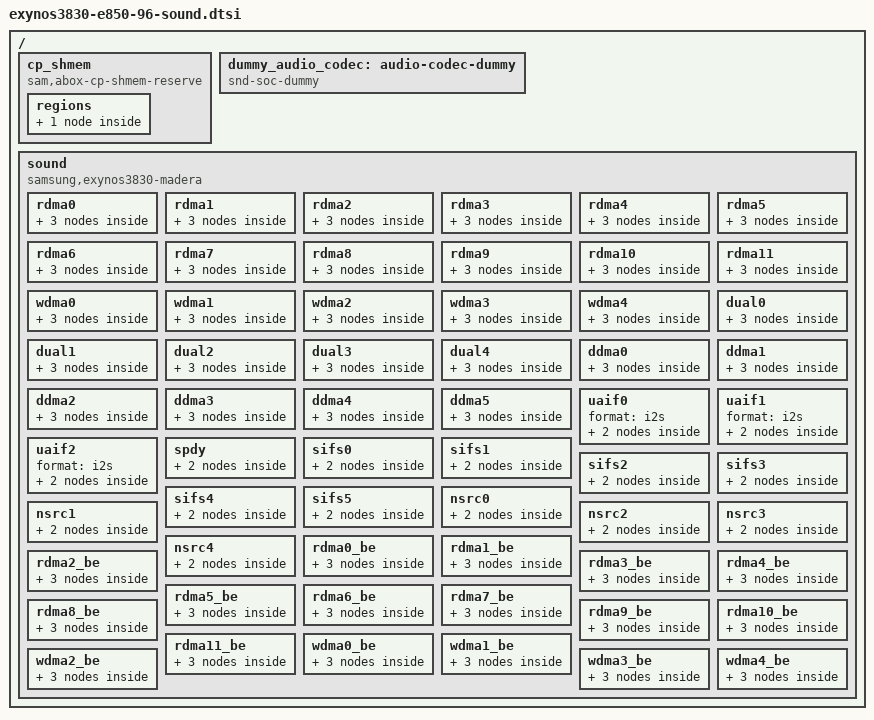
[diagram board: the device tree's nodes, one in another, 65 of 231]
/*
 * SAMSUNG EXYNOS3830 board device tree source
 *
 * Copyright (c) 2018 Samsung Electronics Co., Ltd.
 *		http://www.samsung.com
 *
 * This program is free software; you can redistribute it and/or modify
 * it under the terms of the GNU General Public License version 2 as
 * published by the Free Software Foundation.
 */

/ {
	fragment@sound {
		target-path = "/";
		__overlay__ {
			/*
			 * XXX: This is excerpt from
			 * exynos3830-erd3830-cp-s318ap-sit.dtsi for reserving
			 * memory region used by ABOX (audio) firmware as a
			 * shared memory. If it's not reserved, there will be
			 * MMU translation fault interrupt, leading to kernel
			 * panic. CP (modem) is not present on E850-96 board,
			 * so it's only a workaround to avoid kernel panic.
			 *
			 * Once audio firmware is fixed properly, remove this
			 * node along with CONFIG_SAM_ABOX_CP_SHMEM_RESERVE.
			 */
			cp_shmem {
				compatible = "sam,abox-cp-shmem-reserve";

				cp_num = <0>;
				use_mem_map_on_cp = <1>;

				regions {
					cp {
						region,name = "CP";
						/* 0 = SHMEM_CP */
						region,index = <0>;
						region,rmem = <0>;
						region,offset = <0x00000000>;
						region,size = <0x07900000>;
						region,cached = <0>;
					};
				};
			}; /* end of cp_shmem */

			dummy_audio_codec: audio-codec-dummy {
				compatible = "snd-soc-dummy";
				#sound-dai-cells = <0>;
			};

			sound {
				compatible = "samsung,exynos3830-madera";

				samsung,routing = "ABOX SPDY Capture", "VINPUT_FM",
					"BLUETOOTH SPK", "ABOX UAIF2 Playback",
					"ABOX UAIF2 Capture", "BLUETOOTH MIC";

				samsung,codec = <&abox &abox_uaif_0 &abox_uaif_1 &abox_uaif_2
					&abox_spdy &abox_tplg
					&abox_rdma_0 &abox_rdma_1 &abox_rdma_2 &abox_rdma_3
					&abox_rdma_4 &abox_rdma_5 &abox_rdma_6 &abox_rdma_7
					&abox_rdma_8 &abox_rdma_9 &abox_rdma_10 &abox_rdma_11
					&abox_wdma_0 &abox_wdma_1 &abox_wdma_2 &abox_wdma_3
					&abox_wdma_4 &abox_ddma_0 &abox_ddma_1 &abox_ddma_2
					&abox_ddma_3 &abox_ddma_4 &abox_ddma_5>;
				samsung,prefix = "ABOX", "ABOX", "ABOX", "ABOX",
					"ABOX", "ABOX",
					"ABOX RDMA0", "ABOX RDMA1", "ABOX RDMA2", "ABOX RDMA3",
					"ABOX RDMA4", "ABOX RDMA5", "ABOX RDMA6", "ABOX RDMA7",
					"ABOX RDMA8", "ABOX RDMA9", "ABOX RDMA10", "ABOX RDMA11",
					"ABOX WDMA0", "ABOX WDMA1", "ABOX WDMA2", "ABOX WDMA3",
					"ABOX WDMA4", "ABOX DBG0", "ABOX DBG1", "ABOX DBG2",
					"ABOX DBG3", "ABOX DBG4", "ABOX DBG5";

				samsung,aux = <&abox_tplg>;

				rdma0 {
					cpu {
						sound-dai = <&abox_rdma_0 0>;
					};
					platform {
						sound-dai = <&abox_rdma_0 0>;
					};
					codec {
						sound-dai = <&dummy_audio_codec>;
					};
				};
				rdma1 {
					cpu {
						sound-dai = <&abox_rdma_1 0>;
					};
					platform {
						sound-dai = <&abox_rdma_1 0>;
					};
					codec {
						sound-dai = <&dummy_audio_codec>;
					};
				};
				rdma2 {
					cpu {
						sound-dai = <&abox_rdma_2 0>;
					};
					platform {
						sound-dai = <&abox_rdma_2 0>;
					};
					codec {
						sound-dai = <&dummy_audio_codec>;
					};
				};
				rdma3 {
					cpu {
						sound-dai = <&abox_rdma_3 0>;
					};
					platform {
						sound-dai = <&abox_rdma_3 0>;
					};
					codec {
						sound-dai = <&dummy_audio_codec>;
					};
				};
				rdma4 {
					cpu {
						sound-dai = <&abox_rdma_4 0>;
					};
					platform {
						sound-dai = <&abox_rdma_4 0>;
					};
					codec {
						sound-dai = <&dummy_audio_codec>;
					};
				};
				rdma5 {
					cpu {
						sound-dai = <&abox_rdma_5 0>;
					};
					platform {
						sound-dai = <&abox_rdma_5 0>;
					};
					codec {
						sound-dai = <&dummy_audio_codec>;
					};
				};
				rdma6 {
					cpu {
						sound-dai = <&abox_rdma_6 0>;
					};
					platform {
						sound-dai = <&abox_rdma_6 0>;
					};
					codec {
						sound-dai = <&dummy_audio_codec>;
					};
				};
				rdma7 {
					cpu {
						sound-dai = <&abox_rdma_7 0>;
					};
					platform {
						sound-dai = <&abox_rdma_7 0>;
					};
					codec {
						sound-dai = <&dummy_audio_codec>;
					};
				};
				rdma8 {
					cpu {
						sound-dai = <&abox_rdma_8 0>;
					};
					platform {
						sound-dai = <&abox_rdma_8 0>;
					};
					codec {
						sound-dai = <&dummy_audio_codec>;
					};
				};
				rdma9 {
					cpu {
						sound-dai = <&abox_rdma_9 0>;
					};
					platform {
						sound-dai = <&abox_rdma_9 0>;
					};
					codec {
						sound-dai = <&dummy_audio_codec>;
					};
				};
				rdma10 {
					cpu {
						sound-dai = <&abox_rdma_10 0>;
					};
					platform {
						sound-dai = <&abox_rdma_10 0>;
					};
					codec {
						sound-dai = <&dummy_audio_codec>;
					};
				};
				rdma11 {
					cpu {
						sound-dai = <&abox_rdma_11 0>;
					};
					platform {
						sound-dai = <&abox_rdma_11 0>;
					};
					codec {
						sound-dai = <&dummy_audio_codec>;
					};
				};
				wdma0 {
					cpu {
						sound-dai = <&abox_wdma_0 0>;
					};
					platform {
						sound-dai = <&abox_wdma_0 0>;
					};
					codec {
						sound-dai = <&dummy_audio_codec>;
					};
				};
				wdma1 {
					cpu {
						sound-dai = <&abox_wdma_1 0>;
					};
					platform {
						sound-dai = <&abox_wdma_1 0>;
					};
					codec {
						sound-dai = <&dummy_audio_codec>;
					};
				};
				wdma2 {
					cpu {
						sound-dai = <&abox_wdma_2 0>;
					};
					platform {
						sound-dai = <&abox_wdma_2 0>;
					};
					codec {
						sound-dai = <&dummy_audio_codec>;
					};
				};
				wdma3 {
					cpu {
						sound-dai = <&abox_wdma_3 0>;
					};
					platform {
						sound-dai = <&abox_wdma_3 0>;
					};
					codec {
						sound-dai = <&dummy_audio_codec>;
					};
				};
				wdma4 {
					cpu {
						sound-dai = <&abox_wdma_4 0>;
					};
					platform {
						sound-dai = <&abox_wdma_4 0>;
					};
					codec {
						sound-dai = <&dummy_audio_codec>;
					};
				};
				dual0 {
					cpu {
						sound-dai = <&abox_dual_0>;
					};
					platform {
						sound-dai = <&abox_dual_0>;
					};
					codec {
						sound-dai = <&dummy_audio_codec>;
					};
				};
				dual1 {
					cpu {
						sound-dai = <&abox_dual_1>;
					};
					platform {
						sound-dai = <&abox_dual_1>;
					};
					codec {
						sound-dai = <&dummy_audio_codec>;
					};
				};
				dual2 {
					cpu {
						sound-dai = <&abox_dual_2>;
					};
					platform {
						sound-dai = <&abox_dual_2>;
					};
					codec {
						sound-dai = <&dummy_audio_codec>;
					};
				};
				dual3 {
					cpu {
						sound-dai = <&abox_dual_3>;
					};
					platform {
						sound-dai = <&abox_dual_3>;
					};
					codec {
						sound-dai = <&dummy_audio_codec>;
					};
				};
				dual4 {
					cpu {
						sound-dai = <&abox_dual_4>;
					};
					platform {
						sound-dai = <&abox_dual_4>;
					};
					codec {
						sound-dai = <&dummy_audio_codec>;
					};
				};
				ddma0 {
					cpu {
						sound-dai = <&abox_ddma_0>;
					};
					platform {
						sound-dai = <&abox_ddma_0>;
					};
					codec {
						sound-dai = <&dummy_audio_codec>;
					};
				};
				ddma1 {
					cpu {
						sound-dai = <&abox_ddma_1>;
					};
					platform {
						sound-dai = <&abox_ddma_1>;
					};
					codec {
						sound-dai = <&dummy_audio_codec>;
					};
				};
				ddma2 {
					cpu {
						sound-dai = <&abox_ddma_2>;
					};
					platform {
						sound-dai = <&abox_ddma_2>;
					};
					codec {
						sound-dai = <&dummy_audio_codec>;
					};
				};
				ddma3 {
					cpu {
						sound-dai = <&abox_ddma_3>;
					};
					platform {
						sound-dai = <&abox_ddma_3>;
					};
					codec {
						sound-dai = <&dummy_audio_codec>;
					};
				};
				ddma4 {
					cpu {
						sound-dai = <&abox_ddma_4>;
					};
					platform {
						sound-dai = <&abox_ddma_4>;
					};
					codec {
						sound-dai = <&dummy_audio_codec>;
					};
				};
				ddma5 {
					cpu {
						sound-dai = <&abox_ddma_5>;
					};
					platform {
						sound-dai = <&abox_ddma_5>;
					};
					codec {
						sound-dai = <&dummy_audio_codec>;
					};
				};
				uaif0 {
					format = "i2s";
					cpu {
						sound-dai = <&abox_uaif_0>;
					};
					codec {
						sound-dai = <&codec_aud3004x>;
					};
				};
				uaif1 {
					format = "i2s";
					cpu {
						sound-dai = <&abox_uaif_1>;
					};
					codec {
						sound-dai = <&dummy_audio_codec>;
					};
				};
				uaif2 {
					format = "i2s";
					cpu {
						sound-dai = <&abox_uaif_2>;
					};
					codec {
						sound-dai = <&dummy_audio_codec>;
					};
				};
				spdy {
					cpu {
						sound-dai = <&abox_spdy>;
					};
					codec {
						sound-dai = <&dummy_audio_codec>;
					};
				};
				sifs0 {
					cpu {
						sound-dai = <&abox 0>;
					};
					codec {
						sound-dai = <&dummy_audio_codec>;
					};
				};
				sifs1 {
					cpu {
						sound-dai = <&abox 1>;
					};
					codec {
						sound-dai = <&dummy_audio_codec>;
					};
				};
				sifs2 {
					cpu {
						sound-dai = <&abox 2>;
					};
					codec {
						sound-dai = <&dummy_audio_codec>;
					};
				};
				sifs3 {
					cpu {
						sound-dai = <&abox 3>;
					};
					codec {
						sound-dai = <&dummy_audio_codec>;
					};
				};
				sifs4 {
					cpu {
						sound-dai = <&abox 4>;
					};
					codec {
						sound-dai = <&dummy_audio_codec>;
					};
				};
				sifs5 {
					cpu {
						sound-dai = <&abox 5>;
					};
					codec {
						sound-dai = <&dummy_audio_codec>;
					};
				};
				nsrc0 {
					cpu {
						sound-dai = <&abox 6>;
					};
					codec {
						sound-dai = <&dummy_audio_codec>;
					};
				};
				nsrc1 {
					cpu {
						sound-dai = <&abox 7>;
					};
					codec {
						sound-dai = <&dummy_audio_codec>;
					};
				};
				nsrc2 {
					cpu {
						sound-dai = <&abox 8>;
					};
					codec {
						sound-dai = <&dummy_audio_codec>;
					};
				};
				nsrc3 {
					cpu {
						sound-dai = <&abox 9>;
					};
					codec {
						sound-dai = <&dummy_audio_codec>;
					};
				};
				nsrc4 {
					cpu {
						sound-dai = <&abox 10>;
					};
					codec {
						sound-dai = <&dummy_audio_codec>;
					};
				};
				rdma0_be {
					cpu {
						sound-dai = <&abox_rdma_0 1>;
					};
					platform {
						sound-dai = <&abox_rdma_0 1>;
					};
					codec {
						sound-dai = <&dummy_audio_codec>;
					};
				};
				rdma1_be {
					cpu {
						sound-dai = <&abox_rdma_1 1>;
					};
					platform {
						sound-dai = <&abox_rdma_1 1>;
					};
					codec {
						sound-dai = <&dummy_audio_codec>;
					};
				};
				rdma2_be {
					cpu {
						sound-dai = <&abox_rdma_2 1>;
					};
					platform {
						sound-dai = <&abox_rdma_2 1>;
					};
					codec {
						sound-dai = <&dummy_audio_codec>;
					};
				};
				rdma3_be {
					cpu {
						sound-dai = <&abox_rdma_3 1>;
					};
					platform {
						sound-dai = <&abox_rdma_3 1>;
					};
					codec {
						sound-dai = <&dummy_audio_codec>;
					};
				};
				rdma4_be {
					cpu {
						sound-dai = <&abox_rdma_4 1>;
					};
					platform {
						sound-dai = <&abox_rdma_4 1>;
					};
					codec {
						sound-dai = <&dummy_audio_codec>;
					};
				};
				rdma5_be {
					cpu {
						sound-dai = <&abox_rdma_5 1>;
					};
					platform {
						sound-dai = <&abox_rdma_5 1>;
					};
					codec {
						sound-dai = <&dummy_audio_codec>;
					};
				};
				rdma6_be {
					cpu {
						sound-dai = <&abox_rdma_6 1>;
					};
					platform {
						sound-dai = <&abox_rdma_6 1>;
					};
					codec {
						sound-dai = <&dummy_audio_codec>;
					};
				};
				rdma7_be {
					cpu {
						sound-dai = <&abox_rdma_7 1>;
					};
					platform {
						sound-dai = <&abox_rdma_7 1>;
					};
					codec {
						sound-dai = <&dummy_audio_codec>;
					};
				};
				rdma8_be {
					cpu {
						sound-dai = <&abox_rdma_8 1>;
					};
					platform {
						sound-dai = <&abox_rdma_8 1>;
					};
					codec {
						sound-dai = <&dummy_audio_codec>;
					};
				};
				rdma9_be {
					cpu {
						sound-dai = <&abox_rdma_9 1>;
					};
					platform {
						sound-dai = <&abox_rdma_9 1>;
					};
					codec {
						sound-dai = <&dummy_audio_codec>;
					};
				};
				rdma10_be {
					cpu {
						sound-dai = <&abox_rdma_10 1>;
					};
					platform {
						sound-dai = <&abox_rdma_10 1>;
					};
					codec {
						sound-dai = <&dummy_audio_codec>;
					};
				};
				rdma11_be {
					cpu {
						sound-dai = <&abox_rdma_11 1>;
					};
					platform {
						sound-dai = <&abox_rdma_11 1>;
					};
					codec {
						sound-dai = <&dummy_audio_codec>;
					};
				};
				wdma0_be {
					cpu {
						sound-dai = <&abox_wdma_0 1>;
					};
					platform {
						sound-dai = <&abox_wdma_0 1>;
					};
					codec {
						sound-dai = <&dummy_audio_codec>;
					};
				};
				wdma1_be {
					cpu {
						sound-dai = <&abox_wdma_1 1>;
					};
					platform {
						sound-dai = <&abox_wdma_1 1>;
					};
					codec {
						sound-dai = <&dummy_audio_codec>;
					};
				};
				wdma2_be {
					cpu {
						sound-dai = <&abox_wdma_2 1>;
					};
					platform {
						sound-dai = <&abox_wdma_2 1>;
					};
					codec {
						sound-dai = <&dummy_audio_codec>;
					};
				};
				wdma3_be {
					cpu {
						sound-dai = <&abox_wdma_3 1>;
					};
					platform {
						sound-dai = <&abox_wdma_3 1>;
					};
					codec {
						sound-dai = <&dummy_audio_codec>;
					};
				};
				wdma4_be {
					cpu {
						sound-dai = <&abox_wdma_4 1>;
					};
					platform {
						sound-dai = <&abox_wdma_4 1>;
					};
					codec {
						sound-dai = <&dummy_audio_codec>;
					};
				};
			}; /* end of soundcard */
		}; /* end of __overlay__ */
	}; /* end of fragment */
}; /* end of root */
